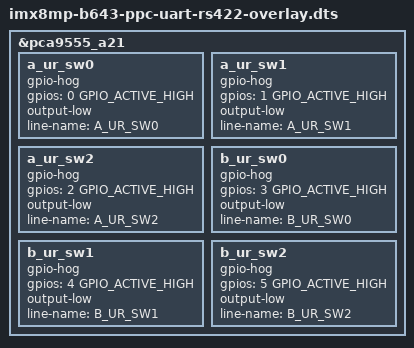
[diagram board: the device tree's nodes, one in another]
/*
// SPDX-License-Identifier: (GPL-2.0+ OR MIT)
/*
 * Copyright 2022 IEI
 *
 * Author: CM Wang <cmwang@ieiworld.com>
 *
 */

/dts-v1/;
/plugin/;

#include <dt-bindings/interrupt-controller/irq.h>
#include <dt-bindings/gpio/gpio.h>

/ {

	fragment@0 {
		target = <&pca9555_a21>;
		__overlay__ {
			a_ur_sw0 {
				gpio-hog;
				gpios = <0 GPIO_ACTIVE_HIGH>;
				output-low;
				line-name = "A_UR_SW0";
			};

			a_ur_sw1 {
				gpio-hog;
				gpios = <1 GPIO_ACTIVE_HIGH>;
				output-low;
				line-name = "A_UR_SW1";
			};

			a_ur_sw2 {
				gpio-hog;
				gpios = <2 GPIO_ACTIVE_HIGH>;
				output-low;
				line-name = "A_UR_SW2";
			};

			b_ur_sw0 {
				gpio-hog;
				gpios = <3 GPIO_ACTIVE_HIGH>;
				output-low;
				line-name = "B_UR_SW0";
			};

			b_ur_sw1 {
				gpio-hog;
				gpios = <4 GPIO_ACTIVE_HIGH>;
				output-low;
				line-name = "B_UR_SW1";
			};

			b_ur_sw2 {
				gpio-hog;
				gpios = <5 GPIO_ACTIVE_HIGH>;
				output-low;
				line-name = "B_UR_SW2";
			};
		};
	};
};
